VERSION "canboat-J1939-curated"

NS_ :

BS_:

BU_: Vector__XXX

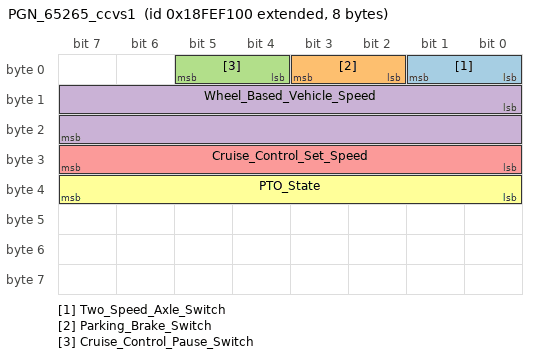
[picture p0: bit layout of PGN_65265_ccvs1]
BO_ 2566844672 PGN_65265_ccvs1: 8 Vector__XXX
 SG_ Two_Speed_Axle_Switch : 0|2@1+ (1.0,0) [0|3] "" Vector__XXX
 SG_ Parking_Brake_Switch : 2|2@1+ (1.0,0) [0|3] "" Vector__XXX
 SG_ Cruise_Control_Pause_Switch : 4|2@1+ (1.0,0) [0|3] "" Vector__XXX
 SG_ Wheel_Based_Vehicle_Speed : 8|16@1+ (0.00390625,0) [0.0|255.99609375] "km/h" Vector__XXX
 SG_ Cruise_Control_Set_Speed : 24|8@1+ (1.0,0) [0|255] "" Vector__XXX
 SG_ PTO_State : 32|8@1+ (1.0,0) [0|255] "" Vector__XXX

CM_ BO_ 2566844672 "J1939: PGN 65265 - Cruise Control / Vehicle Speed 1 (CCVS1) (type: Single)";
CM_ SG_ 2566844672 Two_Speed_Axle_Switch "SPN 1185, bits 1-2; canboat type: NUMBER";
CM_ SG_ 2566844672 Parking_Brake_Switch "SPN 597, bits 3-4; canboat type: NUMBER";
CM_ SG_ 2566844672 Cruise_Control_Pause_Switch "SPN 3885, bits 5-6; canboat type: NUMBER";
CM_ SG_ 2566844672 Wheel_Based_Vehicle_Speed "SPN 84: bits 9-24 (bytes 1-2), little-endian 16-bit, resolution 1/256 km/h per bit, offset 0 — SAE J1939-71; canboat type: NUMBER";
CM_ SG_ 2566844672 Cruise_Control_Set_Speed "SPN 1184: bits 33-40 (byte 4), 1 km/h per bit; canboat type: NUMBER";
CM_ SG_ 2566844672 PTO_State "SPN 73, bits 57-64 (byte 7); canboat type: NUMBER";

CM_ BU_ Vector__XXX "Converted from canboat database (Apache-2.0). J1939 PGN definitions. NOT AN OFFICIAL SAE/NMEA RELEASE; see repository README for attribution requirements.";

BA_DEF_ BO_ "GenMsgCycleTime" INT 0 60000;
BA_DEF_ BO_ "ProtocolType" STRING;
BA_DEF_ "BusType" STRING;
BA_ "BusType" "CAN";
BA_ "ProtocolType" "J1939";

BA_DEF_ BO_ "J1939PGN" INT 0 262143;

BA_ "J1939PGN" BO_ 2566844672 65265;
BA_ "GenMsgCycleTime" BO_ 2566844672 100;

CM_ "Generated from canboat (Apache-2.0). 1 PGN, 6 signal, 0 enum tablosu.";
